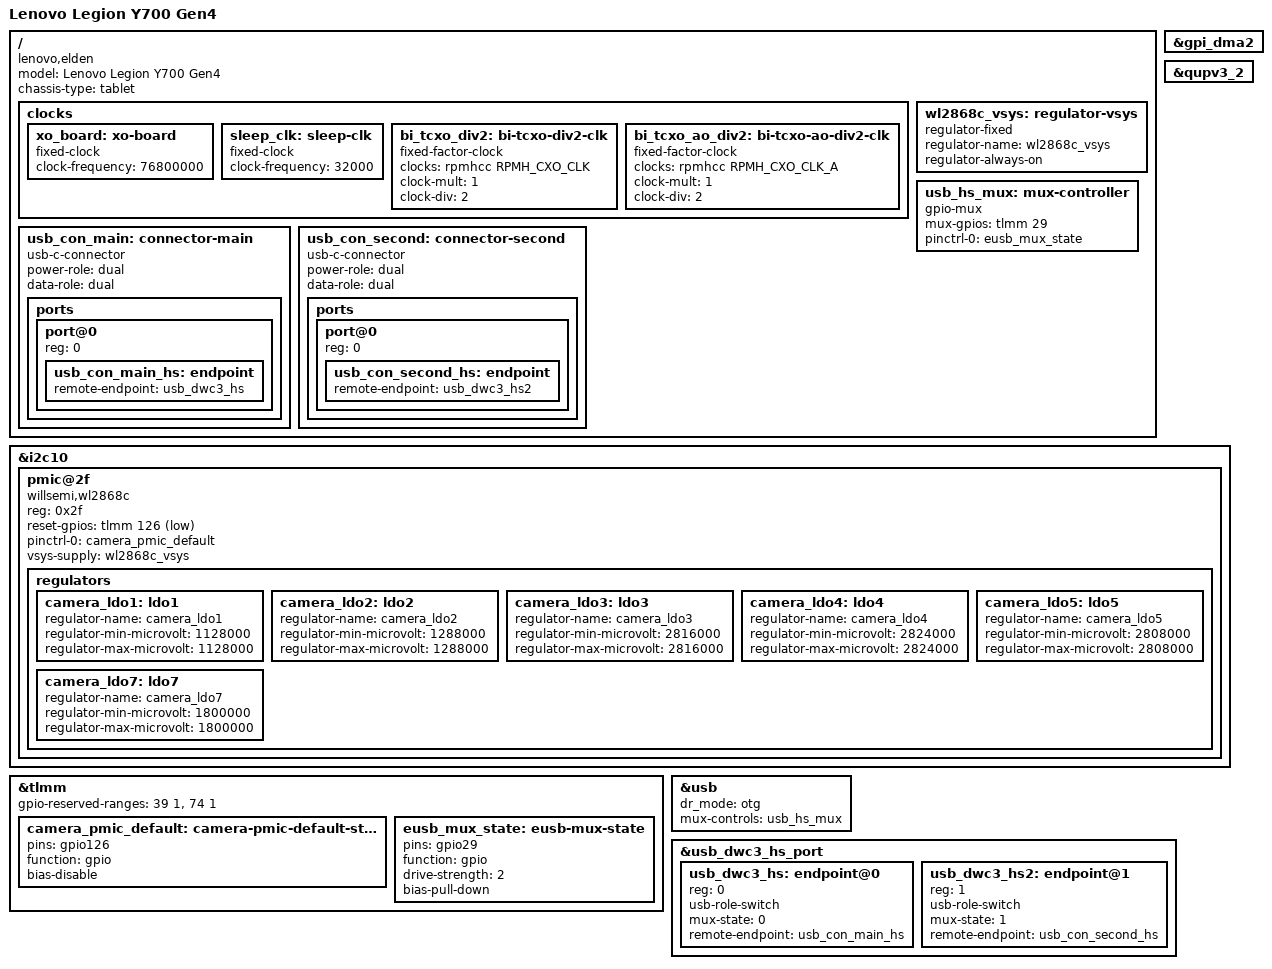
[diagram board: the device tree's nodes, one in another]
// SPDX-License-Identifier: BSD-3-Clause
/*
 * Copyright (c) 2026, Qianhui Xu <xiaqinghuan@mail.ustc.edu.cn>
 */

/dts-v1/;

#include <dt-bindings/gpio/gpio.h>
#include "sm8750.dtsi"

/ {
	model = "Lenovo Legion Y700 Gen4";
	compatible = "lenovo,elden", "qcom,sm8750";
	chassis-type = "tablet";

	clocks {
		xo_board: xo-board {
			compatible = "fixed-clock";
			clock-frequency = <76800000>;
			#clock-cells = <0>;
		};

		sleep_clk: sleep-clk {
			compatible = "fixed-clock";
			clock-frequency = <32000>;
			#clock-cells = <0>;
		};

		bi_tcxo_div2: bi-tcxo-div2-clk {
			compatible = "fixed-factor-clock";
			#clock-cells = <0>;

			clocks = <&rpmhcc RPMH_CXO_CLK>;
			clock-mult = <1>;
			clock-div = <2>;
		};

		bi_tcxo_ao_div2: bi-tcxo-ao-div2-clk {
			compatible = "fixed-factor-clock";
			#clock-cells = <0>;

			clocks = <&rpmhcc RPMH_CXO_CLK_A>;
			clock-mult = <1>;
			clock-div = <2>;
		};
	};

	/*
	 * VSYS of the camera PMIC is the always-on system rail of the tablet.
	 * The SPMI PMICs that generate it are not described yet, so it is
	 * modelled as a fixed regulator without a voltage constraint.
	 */
	wl2868c_vsys: regulator-vsys {
		compatible = "regulator-fixed";
		regulator-name = "wl2868c_vsys";
		regulator-always-on;
	};

	/*
	 * The High Speed D+/D- pair of the USB controller is routed to one of
	 * the two Type-C receptacles through an analog mux whose select input
	 * is GPIO 29 (the stock firmware drives the same line from its UCSI
	 * port manager, so this is a select, not an enable).
	 *
	 * The level left by the bootloader survives eusb_mux_state, which only
	 * programs function and bias and never an output level, but it does not
	 * survive gpio-mux: that driver requests the line as output-low at probe
	 * time.  A mux controller cannot be read back, so the level it is put in
	 * is taken as state 0 and the first select moves the data path.
	 *
	 * idle-state is deliberately left out, i.e. MUX_IDLE_AS_IS: the role
	 * mux deselects the old port immediately before selecting the new one,
	 * and any other idle state would be driven in between, glitching both
	 * receptacles.  Keeping the last state on deselect also matches the
	 * stock firmware, which never parks the line.
	 */
	usb_hs_mux: mux-controller {
		compatible = "gpio-mux";
		#mux-control-cells = <0>;

		mux-gpios = <&tlmm 29 GPIO_ACTIVE_HIGH>;

		pinctrl-names = "default";
		pinctrl-0 = <&eusb_mux_state>;
	};

	usb_con_main: connector-main {
		compatible = "usb-c-connector";
		power-role = "dual";
		data-role = "dual";

		ports {
			#address-cells = <1>;
			#size-cells = <0>;

			port@0 {
				reg = <0>;

				usb_con_main_hs: endpoint {
					remote-endpoint = <&usb_dwc3_hs>;
				};
			};
		};
	};

	usb_con_second: connector-second {
		compatible = "usb-c-connector";
		power-role = "dual";
		data-role = "dual";

		ports {
			#address-cells = <1>;
			#size-cells = <0>;

			port@0 {
				reg = <0>;

				usb_con_second_hs: endpoint {
					remote-endpoint = <&usb_dwc3_hs2>;
				};
			};
		};
	};
};

&gpi_dma2 {
	status = "okay";
};

&qupv3_2 {
	status = "okay";
};

&i2c10 {
	status = "okay";

	pmic@2f {
		compatible = "willsemi,wl2868c";
		reg = <0x2f>;
		reset-gpios = <&tlmm 126 GPIO_ACTIVE_LOW>;
		pinctrl-names = "default";
		pinctrl-0 = <&camera_pmic_default>;
		vsys-supply = <&wl2868c_vsys>;

		regulators {
			/* Voltages include the offsets programmed by stock firmware. */
			camera_ldo1: ldo1 {
				regulator-name = "camera_ldo1";
				regulator-min-microvolt = <1128000>;
				regulator-max-microvolt = <1128000>;
			};

			camera_ldo2: ldo2 {
				regulator-name = "camera_ldo2";
				regulator-min-microvolt = <1288000>;
				regulator-max-microvolt = <1288000>;
			};

			camera_ldo3: ldo3 {
				regulator-name = "camera_ldo3";
				regulator-min-microvolt = <2816000>;
				regulator-max-microvolt = <2816000>;
			};

			camera_ldo4: ldo4 {
				regulator-name = "camera_ldo4";
				regulator-min-microvolt = <2824000>;
				regulator-max-microvolt = <2824000>;
			};

			camera_ldo5: ldo5 {
				regulator-name = "camera_ldo5";
				regulator-min-microvolt = <2808000>;
				regulator-max-microvolt = <2808000>;
			};

			/* LDO6 is not wired out on this board. */
			camera_ldo7: ldo7 {
				regulator-name = "camera_ldo7";
				regulator-min-microvolt = <1800000>;
				regulator-max-microvolt = <1800000>;
			};
		};
	};
};

&tlmm {
	gpio-reserved-ranges = <39 1>, <74 1>;

	camera_pmic_default: camera-pmic-default-state {
		pins = "gpio126";
		function = "gpio";
		bias-disable;
	};
};

&tlmm {
	/*
	 * State of the 2:1 analog mux that selects which receptacle drives the
	 * High Speed D+/D- pair of the USB controller.  The stock firmware
	 * leaves the line as is, so no output level is forced here.
	 */
	eusb_mux_state: eusb-mux-state {
		pins = "gpio29";
		function = "gpio";
		drive-strength = <2>;
		bias-pull-down;
	};
};

&usb {
	dr_mode = "otg";
	mux-controls = <&usb_hs_mux>;
	status = "okay";
};

&usb_dwc3_hs_port {
	#address-cells = <1>;
	#size-cells = <0>;

	/delete-node/ endpoint;

	/* Receptacle A: selected with mux state 0. */
	usb_dwc3_hs: endpoint@0 {
		reg = <0>;

		usb-role-switch;
		mux-state = <0>;
		remote-endpoint = <&usb_con_main_hs>;
	};

	/* Receptacle B: selected with mux state 1. */
	usb_dwc3_hs2: endpoint@1 {
		reg = <1>;

		usb-role-switch;
		mux-state = <1>;
		remote-endpoint = <&usb_con_second_hs>;
	};
};

